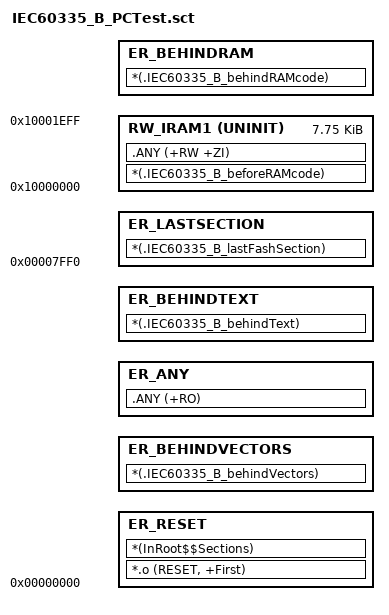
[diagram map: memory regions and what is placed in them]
; *************************************************************
; *** Scatter-Loading Description File generated by uVision ***
; *************************************************************

LR_IROM1 0x0 0x00007FF0  {    ; load region size_region

	ER_RESET +0 {
		*.o (RESET, +First)
		*(InRoot$$Sections)
	}

  	ER_BEHINDVECTORS ImageLimit(ER_RESET) {
		*(.IEC60335_B_behindVectors)	
	}

	ER_ANY ImageLimit(ER_BEHINDVECTORS) ALIGN 4 {
		.ANY (+RO)
	}

	
  	ER_BEHINDTEXT ImageLimit(ER_ANY) {
		*(.IEC60335_B_behindText)	
	}
	
  	RW_IRAM1 0x10000000 UNINIT 0x00001F00  {  ; RW data
		*(.IEC60335_B_beforeRAMcode)   		
		.ANY (+RW +ZI)

	}
	ER_BEHINDRAM ImageLimit(RW_IRAM1) {
		*(.IEC60335_B_behindRAMcode)	
	}

}

LR_IROM2 0x00007FF0 0x10 {

	ER_LASTSECTION +0 {
		*(.IEC60335_B_lastFashSection)
	}	
}
